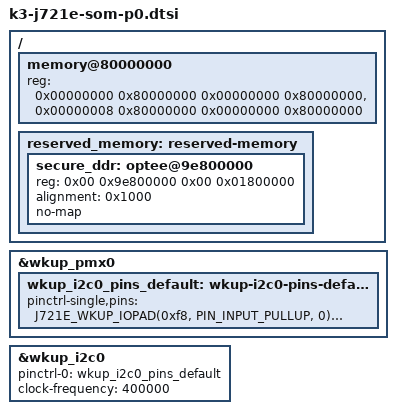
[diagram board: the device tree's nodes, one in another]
// SPDX-License-Identifier: GPL-2.0
/*
 * Copyright (C) 2019 Texas Instruments Incorporated - http://www.ti.com/
 */

/dts-v1/;

#include "k3-j721e.dtsi"

/ {
	memory@80000000 {
		device_type = "memory";
		/* 4G RAM */
		reg = <0x00000000 0x80000000 0x00000000 0x80000000>,
		      <0x00000008 0x80000000 0x00000000 0x80000000>;
	};

	reserved_memory: reserved-memory {
		#address-cells = <2>;
		#size-cells = <2>;
		ranges;

		secure_ddr: optee@9e800000 {
			reg = <0x00 0x9e800000 0x00 0x01800000>;
			alignment = <0x1000>;
			no-map;
		};
	};
};

&wkup_pmx0 {
	wkup_i2c0_pins_default: wkup-i2c0-pins-default {
		pinctrl-single,pins = <
			J721E_WKUP_IOPAD(0xf8, PIN_INPUT_PULLUP, 0) /* (J25) WKUP_I2C0_SCL */
			J721E_WKUP_IOPAD(0xfc, PIN_INPUT_PULLUP, 0) /* (H24) WKUP_I2C0_SDA */
		>;
	};
};

&wkup_i2c0 {
	pinctrl-names = "default";
	pinctrl-0 = <&wkup_i2c0_pins_default>;
	clock-frequency = <400000>;
};
